# PIC32MX320F128L register map
Vendor: Microchip
Registers are 32-bit, read-write, reset 0x0 unless marked. A register's access mark holds for its fields unless they carry their own. Addresses are absolute, and some are shared; only a register's first bit layout is shown; [hi:lo] are bit positions; {n}, {i} and the like mark numbered series.

## _APPO
0x1F880180 _APPO reset not defined — George (power-on value xxxxxxxxxxxxxxxxxxxxxxxxxxxxxxxx)

## _APPI
0x1F880190 _APPI reset not defined — George (power-on value xxxxxxxxxxxxxxxxxxxxxxxxxxxxxxxx)

## INT
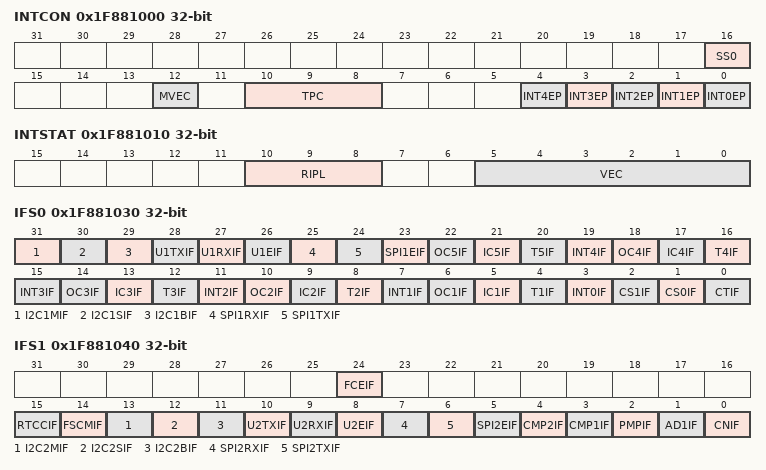
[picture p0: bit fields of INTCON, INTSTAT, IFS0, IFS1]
0x1F881000 INTCON
  [16] SS0, [12] MVEC, [10:8] TPC, [n] INT{n}EP (n=0..4)
0x1F881010 INTSTAT
  [10:8] RIPL, [5:0] VEC
0x1F881020 IPTMR
0x1F881030 IFS0
  [31] I2C1MIF, [30] I2C1SIF, [29] I2C1BIF, [28] U1TXIF, [27] U1RXIF, [26] U1EIF, [25] SPI1RXIF, [24] SPI1TXIF, [23] SPI1EIF, [4n+2] OC{n}IF (n=1..5), [4n+1] IC{n}IF (n=1..5), [4n] T{n}IF (n=1..5), [4n+3] INT{n}IF (n=0..4), [2] CS1IF, [1] CS0IF, [0] CTIF
0x1F881040 IFS1
  [24] FCEIF, [15] RTCCIF, [14] FSCMIF, [13] I2C2MIF, [12] I2C2SIF, [11] I2C2BIF, [10] U2TXIF, [9] U2RXIF, [8] U2EIF, [7] SPI2RXIF, [6] SPI2TXIF, [5] SPI2EIF, [4] CMP2IF, [3] CMP1IF, [2] PMPIF, [1] AD1IF, [0] CNIF
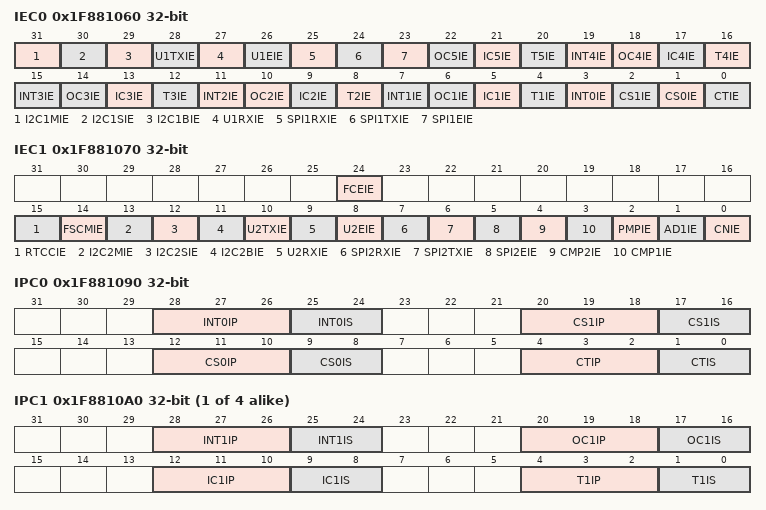
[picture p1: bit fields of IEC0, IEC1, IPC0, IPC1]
0x1F881060 IEC0
  [31] I2C1MIE, [30] I2C1SIE, [29] I2C1BIE, [28] U1TXIE, [27] U1RXIE, [26] U1EIE, [25] SPI1RXIE, [24] SPI1TXIE, [23] SPI1EIE, [4n+2] OC{n}IE (n=1..5), [4n+1] IC{n}IE (n=1..5), [4n] T{n}IE (n=1..5), [4n+3] INT{n}IE (n=0..4), [2] CS1IE, [1] CS0IE, [0] CTIE
0x1F881070 IEC1
  [24] FCEIE, [15] RTCCIE, [14] FSCMIE, [13] I2C2MIE, [12] I2C2SIE, [11] I2C2BIE, [10] U2TXIE, [9] U2RXIE, [8] U2EIE, [7] SPI2RXIE, [6] SPI2TXIE, [5] SPI2EIE, [4] CMP2IE, [3] CMP1IE, [2] PMPIE, [1] AD1IE, [0] CNIE
0x1F881090 IPC0
  [28:26] INT0IP, [25:24] INT0IS, [20:18] CS1IP, [17:16] CS1IS, [12:10] CS0IP, [9:8] CS0IS, [4:2] CTIP, [1:0] CTIS
{0x1F881090+0x10*i} IPC{i} (i=1..4)
  [28:26] INT{i}IP, [25:24] INT{i}IS, [20:18] OC{i}IP, [17:16] OC{i}IS, [12:10] IC{i}IP, [9:8] IC{i}IS, [4:2] T{i}IP, [1:0] T{i}IS
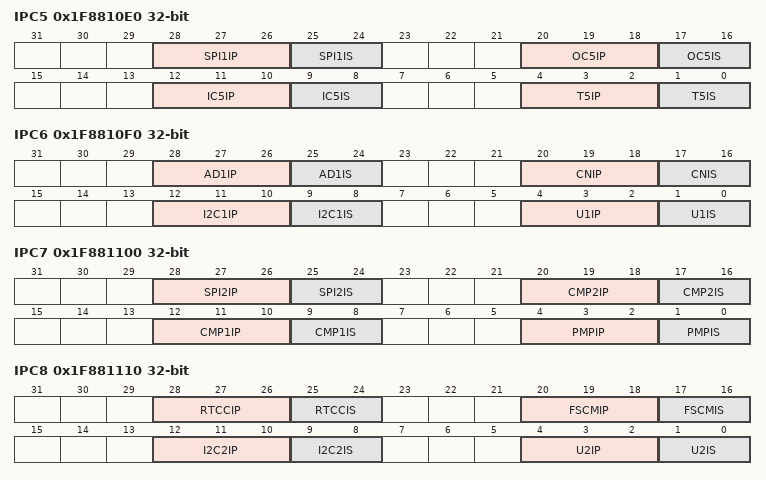
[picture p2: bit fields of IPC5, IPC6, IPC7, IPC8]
0x1F8810E0 IPC5
  [28:26] SPI1IP, [25:24] SPI1IS, [20:18] OC5IP, [17:16] OC5IS, [12:10] IC5IP, [9:8] IC5IS, [4:2] T5IP, [1:0] T5IS
0x1F8810F0 IPC6
  [28:26] AD1IP, [25:24] AD1IS, [20:18] CNIP, [17:16] CNIS, [12:10] I2C1IP, [9:8] I2C1IS, [4:2] U1IP, [1:0] U1IS
0x1F881100 IPC7
  [28:26] SPI2IP, [25:24] SPI2IS, [20:18] CMP2IP, [17:16] CMP2IS, [12:10] CMP1IP, [9:8] CMP1IS, [4:2] PMPIP, [1:0] PMPIS
0x1F881110 IPC8
  [28:26] RTCCIP, [25:24] RTCCIS, [20:18] FSCMIP, [17:16] FSCMIS, [12:10] I2C2IP, [9:8] I2C2IS, [4:2] U2IP, [1:0] U2IS
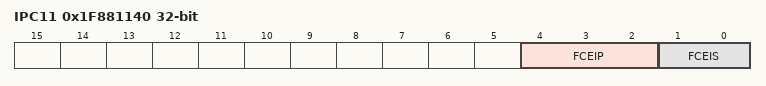
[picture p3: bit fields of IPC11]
0x1F881140 IPC11
  [4:2] FCEIP, [1:0] FCEIS

## BMX
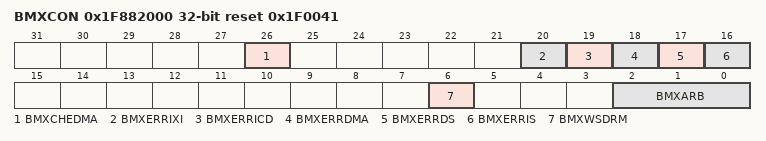
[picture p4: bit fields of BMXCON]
0x1F882000 BMXCON reset 0x1F0041
  [26] BMXCHEDMA, [20] BMXERRIXI, [19] BMXERRICD, [18] BMXERRDMA, [17] BMXERRDS, [16] BMXERRIS, [6] BMXWSDRM, [2:0] BMXARB
0x1F882010 BMXDKPBA
0x1F882020 BMXDUDBA
0x1F882030 BMXDUPBA
0x1F882040 BMXDRMSZ ro reset 0x20000
0x1F882050 BMXPUPBA
0x1F882060 BMXPFMSZ ro reset 0x80000
0x1F882070 BMXBOOTSZ ro reset 0x3000

## PCACHE
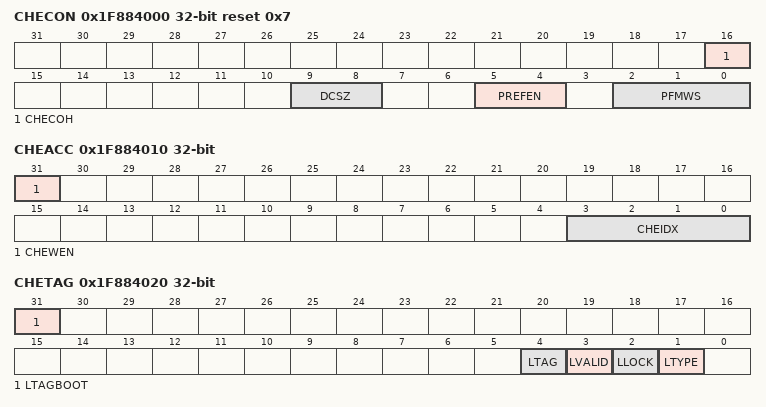
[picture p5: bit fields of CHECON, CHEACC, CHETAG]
0x1F884000 CHECON reset 0x7
  [16] CHECOH, [9:8] DCSZ, [5:4] PREFEN, [2:0] PFMWS
0x1F884010 CHEACC
  [31] CHEWEN, [3:0] CHEIDX
0x1F884020 CHETAG reset not defined — (power-on value 0xxxxxxxxxxxxxxxxxxxxxxxxxxx0010)
  [31] LTAGBOOT, [4] LTAG, [3] LVALID, [2] LLOCK, [1] LTYPE
0x1F884030 CHEMSK
  [15:5] LMASK
{0x1F884040+0x10*i} CHEW{i} reset not defined (i=0..3) — (power-on value xxxxxxxxxxxxxxxxxxxxxxxxxxxxxxxx)
0x1F884080 CHELRU
  [24:0] CHELRU
0x1F884090 CHEHIT reset not defined — (power-on value xxxxxxxxxxxxxxxxxxxxxxxxxxxxxxxx)
  [31:0] CHEHIT — (can only be cleared)
0x1F8840A0 CHEMIS reset not defined — (power-on value xxxxxxxxxxxxxxxxxxxxxxxxxxxxxxxx)
  [31:0] CHEMIS — (can only be cleared)
0x1F8840C0 CHEPFABT reset not defined — (power-on value xxxxxxxxxxxxxxxxxxxxxxxxxxxxxxxx)
  [31:0] CHEPFABT — (can only be cleared)

## YPAA_Ports
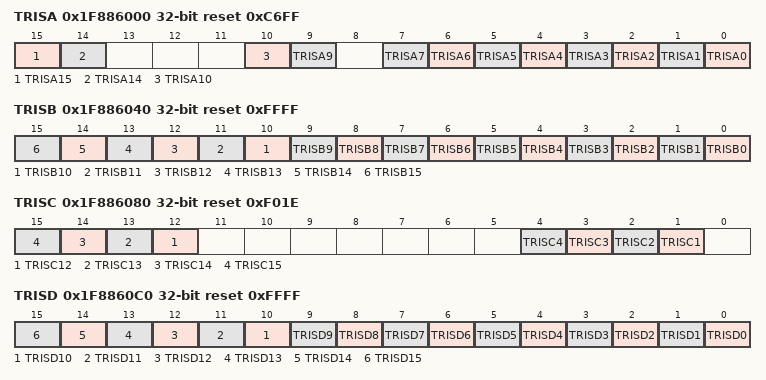
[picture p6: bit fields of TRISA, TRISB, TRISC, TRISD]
0x1F886000 TRISA reset 0xC6FF
  [15] TRISA15, [14] TRISA14, [10] TRISA10, [9] TRISA9, [n] TRISA{n} (n=0..7)
0x1F886040 TRISB reset 0xFFFF
  [n] TRISB{n} (n=0..15)
0x1F886080 TRISC reset 0xF01E
  [n] TRISC{n} (n=12..15), [n] TRISC{n} (n=1..4)
0x1F8860C0 TRISD reset 0xFFFF
  [n] TRISD{n} (n=0..15)
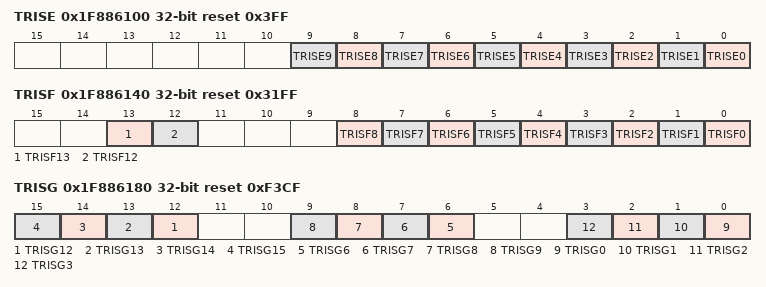
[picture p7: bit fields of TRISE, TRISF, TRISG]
0x1F886100 TRISE reset 0x3FF
  [n] TRISE{n} (n=0..9)
0x1F886140 TRISF reset 0x31FF
  [13] TRISF13, [12] TRISF12, [n] TRISF{n} (n=0..8)
0x1F886180 TRISG reset 0xF3CF
  [n] TRISG{n} (n=12..15), [n] TRISG{n} (n=6..9), [n] TRISG{n} (n=0..3)

## PORTA
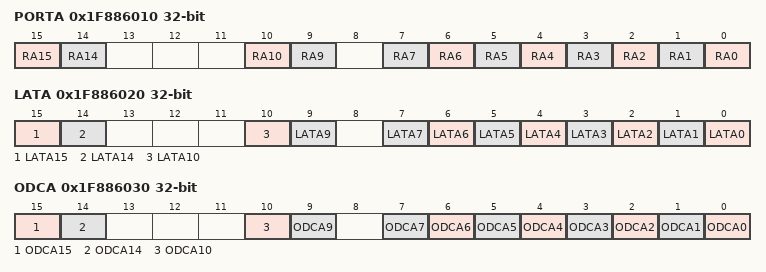
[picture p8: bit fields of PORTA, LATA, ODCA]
0x1F886010 PORTA reset not defined — (power-on value ----------------xx---xx-xxxxxxxx)
  [15] RA15, [14] RA14, [10] RA10, [9] RA9, [n] RA{n} (n=0..7)
0x1F886020 LATA reset not defined — (power-on value ----------------xx---xx-xxxxxxxx)
  [15] LATA15, [14] LATA14, [10] LATA10, [9] LATA9, [n] LATA{n} (n=0..7)
0x1F886030 ODCA
  [15] ODCA15, [14] ODCA14, [10] ODCA10, [9] ODCA9, [n] ODCA{n} (n=0..7)

## PORTB
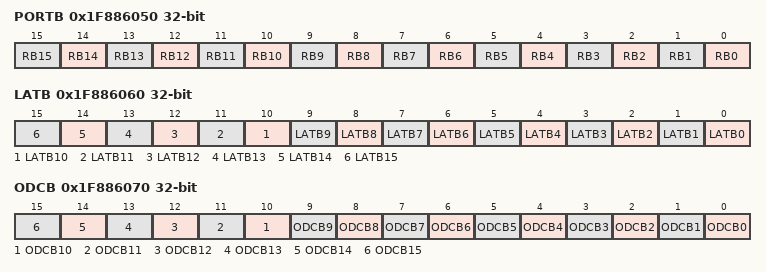
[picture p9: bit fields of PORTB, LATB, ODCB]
0x1F886050 PORTB reset not defined — (power-on value ----------------xxxxxxxxxxxxxxxx)
  [n] RB{n} (n=0..15)
0x1F886060 LATB reset not defined — (power-on value ----------------xxxxxxxxxxxxxxxx)
  [n] LATB{n} (n=0..15)
0x1F886070 ODCB
  [n] ODCB{n} (n=0..15)

## PORTC
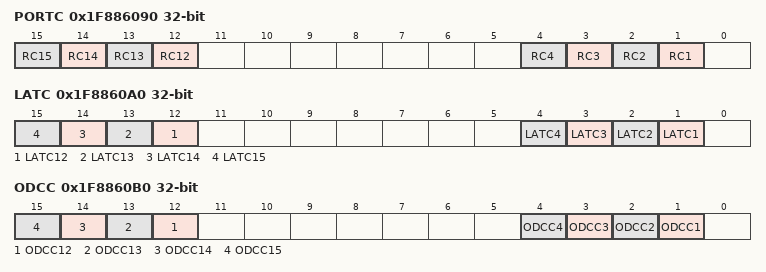
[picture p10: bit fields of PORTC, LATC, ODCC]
0x1F886090 PORTC reset not defined — (power-on value ----------------xxxx-------xxxx-)
  [n] RC{n} (n=12..15), [n] RC{n} (n=1..4)
0x1F8860A0 LATC reset not defined — (power-on value ----------------xxxx-------xxxx-)
  [n] LATC{n} (n=12..15), [n] LATC{n} (n=1..4)
0x1F8860B0 ODCC
  [n] ODCC{n} (n=12..15), [n] ODCC{n} (n=1..4)

## PORTD
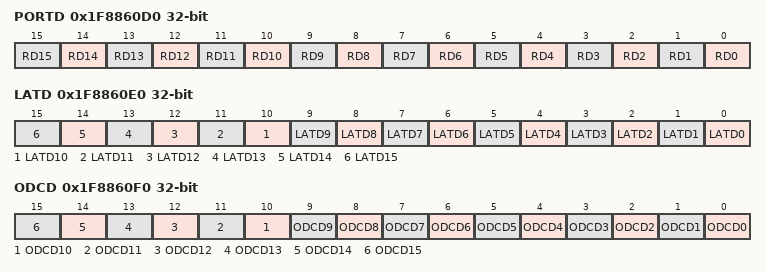
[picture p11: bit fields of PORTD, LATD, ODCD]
0x1F8860D0 PORTD reset not defined — (power-on value ----------------xxxxxxxxxxxxxxxx)
  [n] RD{n} (n=0..15)
0x1F8860E0 LATD reset not defined — (power-on value ----------------xxxxxxxxxxxxxxxx)
  [n] LATD{n} (n=0..15)
0x1F8860F0 ODCD
  [n] ODCD{n} (n=0..15)

## PORTE
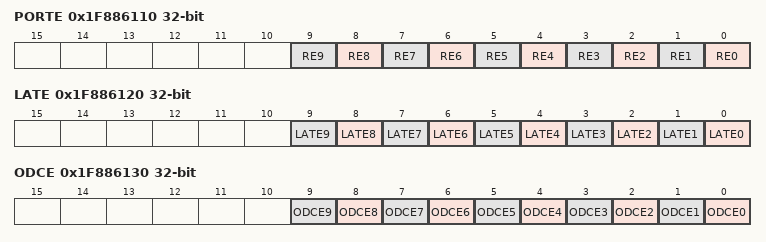
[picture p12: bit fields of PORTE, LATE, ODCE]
0x1F886110 PORTE reset not defined — (power-on value ----------------------xxxxxxxxxx)
  [n] RE{n} (n=0..9)
0x1F886120 LATE reset not defined — (power-on value ----------------------xxxxxxxxxx)
  [n] LATE{n} (n=0..9)
0x1F886130 ODCE
  [n] ODCE{n} (n=0..9)

## PORTF
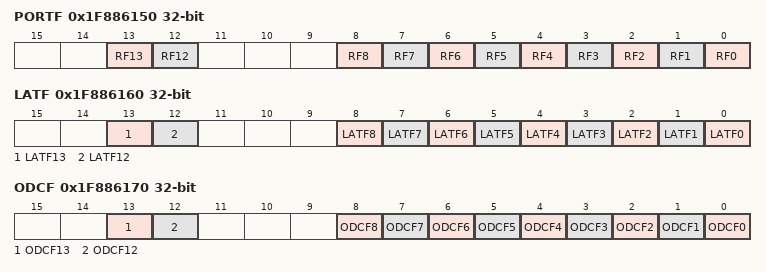
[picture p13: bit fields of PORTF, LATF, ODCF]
0x1F886150 PORTF reset not defined — (power-on value ------------------xx---xxxxxxxxx)
  [13] RF13, [12] RF12, [n] RF{n} (n=0..8)
0x1F886160 LATF reset not defined — (power-on value ------------------xx---xxxxxxxxx)
  [13] LATF13, [12] LATF12, [n] LATF{n} (n=0..8)
0x1F886170 ODCF
  [13] ODCF13, [12] ODCF12, [n] ODCF{n} (n=0..8)

## PORTG
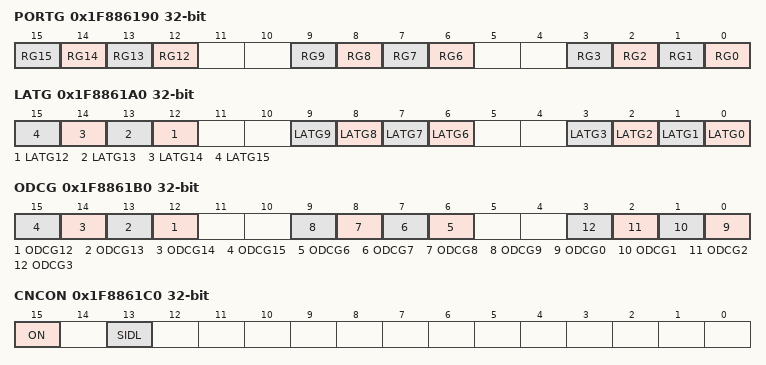
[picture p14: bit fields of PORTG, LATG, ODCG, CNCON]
0x1F886190 PORTG reset not defined — (power-on value ----------------xxxx--xxxx--xxxx)
  [n] RG{n} (n=12..15), [n] RG{n} (n=6..9), [n] RG{n} (n=0..3)
0x1F8861A0 LATG reset not defined — (power-on value ----------------xxxx--xxxx--xxxx)
  [n] LATG{n} (n=12..15), [n] LATG{n} (n=6..9), [n] LATG{n} (n=0..3)
0x1F8861B0 ODCG
  [n] ODCG{n} (n=12..15), [n] ODCG{n} (n=6..9), [n] ODCG{n} (n=0..3)
0x1F8861C0 CNCON
  [15] ON, [13] SIDL
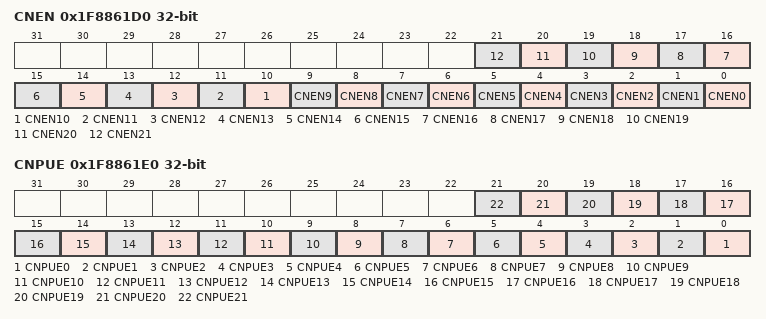
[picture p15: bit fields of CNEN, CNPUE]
0x1F8861D0 CNEN
  [n] CNEN{n} (n=0..21)
0x1F8861E0 CNPUE
  [n] CNPUE{n} (n=0..21)
